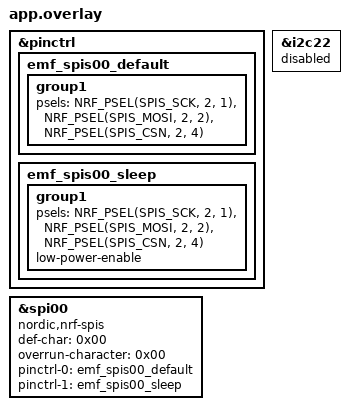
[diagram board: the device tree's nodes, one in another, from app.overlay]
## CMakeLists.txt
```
cmake_minimum_required(VERSION 3.20.0)

set(DTC_OVERLAY_FILE "${CMAKE_CURRENT_SOURCE_DIR}/app.overlay" CACHE STRING "" FORCE)

find_package(Zephyr REQUIRED HINTS $ENV{ZEPHYR_BASE})

project(ble_gatt_service_try)

target_sources(app PRIVATE src/main.c src/emf_data.c src/emf_spi.c)

target_compile_definitions(app PRIVATE
  EMF_SPIS_BOARD_NAME="XIAO"
)
```

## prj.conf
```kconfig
CONFIG_MULTITHREADING=y

CONFIG_BT=y
CONFIG_BT_PERIPHERAL=y
CONFIG_BT_DEVICE_NAME="XIAO_EMF"
CONFIG_BT_MAX_CONN=1

CONFIG_BT_LONG_WQ_PRIO=0
CONFIG_SYSTEM_WORKQUEUE_STACK_SIZE=8192
CONFIG_BT_LONG_WQ_STACK_SIZE=8192
CONFIG_BT_RX_STACK_SIZE=4096
CONFIG_BT_HCI_TX_STACK_SIZE=2048
CONFIG_MPSL_WORK_STACK_SIZE=8192
CONFIG_STACK_SENTINEL=y
CONFIG_THREAD_STACK_INFO=y
CONFIG_INIT_STACKS=y

CONFIG_LOG=y
CONFIG_PRINTK=y
CONFIG_MAIN_STACK_SIZE=8192

CONFIG_SERIAL=y
CONFIG_UART_INTERRUPT_DRIVEN=y

CONFIG_SPI=y
CONFIG_SPI_SLAVE=y
CONFIG_NRFX_SPIS=y

CONFIG_BT_BUF_ACL_TX_SIZE=251
CONFIG_BT_BUF_ACL_RX_SIZE=251
CONFIG_BT_L2CAP_TX_MTU=247
CONFIG_BT_CTLR_DATA_LENGTH_MAX=251
```

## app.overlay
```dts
#include <zephyr/dt-bindings/pinctrl/nrf-pinctrl.h>

&pinctrl {
	emf_spis00_default: emf_spis00_default {
		group1 {
			psels = <NRF_PSEL(SPIS_SCK, 2, 1)>,
				<NRF_PSEL(SPIS_MOSI, 2, 2)>,
				<NRF_PSEL(SPIS_CSN, 2, 4)>;
		};
	};

	emf_spis00_sleep: emf_spis00_sleep {
		group1 {
			psels = <NRF_PSEL(SPIS_SCK, 2, 1)>,
				<NRF_PSEL(SPIS_MOSI, 2, 2)>,
				<NRF_PSEL(SPIS_CSN, 2, 4)>;
			low-power-enable;
		};
	};
};

&spi00 {
	compatible = "nordic,nrf-spis";
	status = "okay";
	def-char = <0x00>;
	overrun-character = <0x00>;
	pinctrl-0 = <&emf_spis00_default>;
	pinctrl-1 = <&emf_spis00_sleep>;
	pinctrl-names = "default", "sleep";
	/delete-property/ rx-delay-supported;
	/delete-property/ rx-delay;
};

&i2c22 {
	status = "disabled";
};
```

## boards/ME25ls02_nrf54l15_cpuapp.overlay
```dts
#include <zephyr/dt-bindings/pinctrl/nrf-pinctrl.h>

&pinctrl {
	emf_spis00_default: emf_spis00_default {
		group1 {
			psels = <NRF_PSEL(SPIS_SCK, 2, 6)>,
				<NRF_PSEL(SPIS_MOSI, 2, 8)>,
				<NRF_PSEL(SPIS_MISO, 2, 9)>,
				<NRF_PSEL(SPIS_CSN, 2, 10)>;
		};
	};

	emf_spis00_sleep: emf_spis00_sleep {
		group1 {
			psels = <NRF_PSEL(SPIS_SCK, 2, 6)>,
				<NRF_PSEL(SPIS_MOSI, 2, 8)>,
				<NRF_PSEL(SPIS_MISO, 2, 9)>,
				<NRF_PSEL(SPIS_CSN, 2, 10)>;
			low-power-enable;
		};
	};
};

&spi00 {
	compatible = "nordic,nrf-spis";
	status = "okay";
	def-char = <0x00>;
	overrun-character = <0x00>;
	pinctrl-0 = <&emf_spis00_default>;
	pinctrl-1 = <&emf_spis00_sleep>;
	pinctrl-names = "default", "sleep";
	/delete-property/ rx-delay-supported;
	/delete-property/ rx-delay;
};
```

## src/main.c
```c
#include <zephyr/kernel.h>
#include <zephyr/types.h>
#include <zephyr/sys/printk.h>

#include <string.h>
#include <errno.h>

#include <zephyr/bluetooth/bluetooth.h>
#include <zephyr/bluetooth/conn.h>
#include <zephyr/bluetooth/gatt.h>
#include <zephyr/bluetooth/uuid.h>

#include "emf_data.h"

/*
 * BLE services:
 *
 * 1) Battery Service
 *    Service UUID:        0x180F
 *    Battery Level UUID:  0x2A19, read + notify
 *    BATS UUID:           0x2BED, read + notify
 *
 * 2) Data Service
 *    Service UUID:        00000000-8e22-4541-9d4c-21edae82ed19
 *    emf_values UUID:     00000001-8e22-4541-9d4c-21edae82ed19
 *    Properties:          indicate
 *    Payload size:        200 bytes
 */

#define EMF_VALUES_SIZE 200
#define EMF_PAYLOAD_DELAY_MS 2000

#define DATA_SERVICE_UUID_VAL \
	BT_UUID_128_ENCODE(0x00000000, 0x8e22, 0x4541, 0x9d4c, 0x21edae82ed19)

#define EMF_VALUES_UUID_VAL \
	BT_UUID_128_ENCODE(0x00000001, 0x8e22, 0x4541, 0x9d4c, 0x21edae82ed19)

static struct bt_uuid_128 data_service_uuid =
	BT_UUID_INIT_128(DATA_SERVICE_UUID_VAL);

static struct bt_uuid_128 emf_values_uuid =
	BT_UUID_INIT_128(EMF_VALUES_UUID_VAL);

/* Current BLE connection */
static struct bt_conn *current_conn;

/* Battery values */
static uint8_t battery_level = 95;
static uint8_t battery_status = 0;

/* CCC states */
static bool battery_level_notify_enabled;
static bool battery_status_notify_enabled;
static bool emf_indicate_enabled;

/* EMF data */
static uint8_t emf_values[EMF_VALUES_SIZE];
static uint8_t emf_payload[EMF_PAYLOAD_SIZE];
static size_t emf_payload_offset;
static bool emf_indication_busy;
static int64_t next_emf_message_time;

/* ------------------------------------------------ */
/* Read callbacks                                   */
/* ------------------------------------------------ */

static ssize_t read_u8_value(struct bt_conn *conn,
			     const struct bt_gatt_attr *attr,
			     void *buf,
			     uint16_t len,
			     uint16_t offset)
{
	const uint8_t *value = attr->user_data;

	return bt_gatt_attr_read(conn, attr, buf, len, offset,
				 value, sizeof(*value));
}

static ssize_t read_emf_values(struct bt_conn *conn,
			       const struct bt_gatt_attr *attr,
			       void *buf,
			       uint16_t len,
			       uint16_t offset)
{
	const uint8_t *value = attr->user_data;

	return bt_gatt_attr_read(conn, attr, buf, len, offset,
				 value, EMF_VALUES_SIZE);
}

/* ------------------------------------------------ */
/* CCC callbacks                                    */
/* ------------------------------------------------ */

static void battery_level_ccc_changed(const struct bt_gatt_attr *attr,
				      uint16_t value)
{
	battery_level_notify_enabled = (value == BT_GATT_CCC_NOTIFY);

	printk("Battery Level notify: %s\n",
	       battery_level_notify_enabled ? "enabled" : "disabled");
}

static void battery_status_ccc_changed(const struct bt_gatt_attr *attr,
				       uint16_t value)
{
	battery_status_notify_enabled = (value == BT_GATT_CCC_NOTIFY);

	printk("Battery Status notify: %s\n",
	       battery_status_notify_enabled ? "enabled" : "disabled");
}

static void emf_ccc_changed(const struct bt_gatt_attr *attr,
			    uint16_t value)
{
	emf_indicate_enabled = (value == BT_GATT_CCC_INDICATE);

	if (emf_indicate_enabled) {
		emf_payload_offset = 0;
		next_emf_message_time = 0;
	}

	printk("EMF indication: %s\n",
	       emf_indicate_enabled ? "enabled" : "disabled");
}

/* ------------------------------------------------ */
/* Battery Service                                  */
/* ------------------------------------------------ */

/*
 * battery_svc attrs:
 *
 * [0] Primary Service
 *
 * Battery Level:
 * [1] Characteristic Declaration
 * [2] Characteristic Value
 * [3] Characteristic User Description
 * [4] CCC
 *
 * Battery Status:
 * [5] Characteristic Declaration
 * [6] Characteristic Value
 * [7] Characteristic User Description
 * [8] CCC
 */

BT_GATT_SERVICE_DEFINE(battery_svc,
	BT_GATT_PRIMARY_SERVICE(BT_UUID_DECLARE_16(0x180F)),

	BT_GATT_CHARACTERISTIC(BT_UUID_DECLARE_16(0x2A19),
			       BT_GATT_CHRC_READ | BT_GATT_CHRC_NOTIFY,
			       BT_GATT_PERM_READ,
			       read_u8_value,
			       NULL,
			       &battery_level),

	BT_GATT_CUD("Battery Level", BT_GATT_PERM_READ),

	BT_GATT_CCC(battery_level_ccc_changed,
		    BT_GATT_PERM_READ | BT_GATT_PERM_WRITE),

	BT_GATT_CHARACTERISTIC(BT_UUID_DECLARE_16(0x2BED),
			       BT_GATT_CHRC_READ | BT_GATT_CHRC_NOTIFY,
			       BT_GATT_PERM_READ,
			       read_u8_value,
			       NULL,
			       &battery_status),

	BT_GATT_CUD("Battery Status", BT_GATT_PERM_READ),

	BT_GATT_CCC(battery_status_ccc_changed,
		    BT_GATT_PERM_READ | BT_GATT_PERM_WRITE)
);

/* ------------------------------------------------ */
/* Data Service                                     */
/* ------------------------------------------------ */

/*
 * data_svc attrs:
 *
 * [0] Primary Service
 * [1] Characteristic Declaration
 * [2] Characteristic Value
 * [3] Characteristic User Description
 * [4] CCC
 */

BT_GATT_SERVICE_DEFINE(data_svc,
	BT_GATT_PRIMARY_SERVICE(&data_service_uuid.uuid),

	BT_GATT_CHARACTERISTIC(&emf_values_uuid.uuid,
			       BT_GATT_CHRC_READ | BT_GATT_CHRC_INDICATE,
			       BT_GATT_PERM_READ,
			       read_emf_values,
			       NULL,
			       emf_values),

	BT_GATT_CUD("EMF Values", BT_GATT_PERM_READ),

	BT_GATT_CCC(emf_ccc_changed,
		    BT_GATT_PERM_READ | BT_GATT_PERM_WRITE)
);

/* ------------------------------------------------ */
/* Battery notify                                   */
/* ------------------------------------------------ */

static void send_battery_level_notify(void)
{
	if (!current_conn || !battery_level_notify_enabled) {
		return;
	}

	int err = bt_gatt_notify(current_conn,
				 &battery_svc.attrs[2],
				 &battery_level,
				 sizeof(battery_level));

	if (err) {
		printk("Battery Level notify failed: %d\n", err);
	}
}

static void send_battery_status_notify(void)
{
	if (!current_conn || !battery_status_notify_enabled) {
		return;
	}

	int err = bt_gatt_notify(current_conn,
				 &battery_svc.attrs[6],
				 &battery_status,
				 sizeof(battery_status));

	if (err) {
		printk("Battery Status notify failed: %d\n", err);
	}
}

/* ------------------------------------------------ */
/* EMF indication                                   */
/* ------------------------------------------------ */

static void emf_indication_complete(struct bt_conn *conn,
				    struct bt_gatt_indicate_params *params,
				    uint8_t err)
{
	emf_indication_busy = false;

	if (emf_payload_offset >= EMF_PAYLOAD_SIZE) {
		next_emf_message_time = k_uptime_get() + EMF_PAYLOAD_DELAY_MS;
	}

	printk("EMF indication complete, err=%u\n", err);
}

static struct bt_gatt_indicate_params emf_ind_params;

static int send_emf_values_indication(const uint8_t *data, uint16_t size)
{
	if (!current_conn) {
		return -ENOTCONN;
	}

	if (!emf_indicate_enabled) {
		return -EACCES;
	}

	if (emf_indication_busy) {
		return -EBUSY;
	}

	if (size > EMF_VALUES_SIZE) {
		return -EINVAL;
	}

	memcpy(emf_values, data, size);

	emf_ind_params.attr = &data_svc.attrs[2];
	emf_ind_params.func = emf_indication_complete;
	emf_ind_params.data = emf_values;
	emf_ind_params.len = size;

	emf_indication_busy = true;

	int err = bt_gatt_indicate(current_conn, &emf_ind_params);

	if (err) {
		emf_indication_busy = false;
		printk("EMF indication failed: %d\n", err);
	}

	return err;
}

static int send_next_emf_chunk(void)
{
	size_t chunk_size;
	int err;

	if (emf_payload_offset >= EMF_PAYLOAD_SIZE) {
		emf_payload_offset = 0;
	}

	chunk_size = EMF_PAYLOAD_SIZE - emf_payload_offset;
	if (chunk_size > EMF_VALUES_SIZE) {
		chunk_size = EMF_VALUES_SIZE;
	}

	err = send_emf_values_indication(&emf_payload[emf_payload_offset],
					 chunk_size);
	if (err) {
		return err;
	}

	printk("EMF chunk sent: offset=%u size=%u\n",
	       (unsigned int)emf_payload_offset,
	       (unsigned int)chunk_size);

	emf_payload_offset += chunk_size;

	return 0;
}

/* ------------------------------------------------ */
/* Connection callbacks                             */
/* ------------------------------------------------ */

static int start_advertising(void);
static void advertising_work_handler(struct k_work *work);

static K_WORK_DELAYABLE_DEFINE(advertising_work, advertising_work_handler);

static void connected(struct bt_conn *conn, uint8_t err)
{
	if (err) {
		printk("Connection failed, err=%u\n", err);
		return;
	}

	current_conn = bt_conn_ref(conn);

	printk("Connected\n");
}

static void disconnected(struct bt_conn *conn, uint8_t reason)
{
	printk("Disconnected, reason=%u\n", reason);

	if (current_conn) {
		bt_conn_unref(current_conn);
		current_conn = NULL;
	}

	battery_level_notify_enabled = false;
	battery_status_notify_enabled = false;
	emf_indicate_enabled = false;
	emf_indication_busy = false;

	k_work_schedule(&advertising_work, K_MSEC(100));
}

BT_CONN_CB_DEFINE(conn_callbacks) = {
	.connected = connected,
	.disconnected = disconnected,
};

/* ------------------------------------------------ */
/* Advertising                                      */
/* ------------------------------------------------ */

static const struct bt_data ad[] = {
	BT_DATA_BYTES(BT_DATA_FLAGS, BT_LE_AD_GENERAL | BT_LE_AD_NO_BREDR),

	BT_DATA(BT_DATA_NAME_COMPLETE,
		CONFIG_BT_DEVICE_NAME,
		sizeof(CONFIG_BT_DEVICE_NAME) - 1),

	BT_DATA_BYTES(BT_DATA_UUID16_ALL,
		      BT_UUID_16_ENCODE(0x180F)),
};

static int start_advertising(void)
{
	int err = bt_le_adv_start(BT_LE_ADV_CONN_FAST_1,
				  ad,
				  ARRAY_SIZE(ad),
				  NULL,
				  0);

	if (err) {
		return err;
	}

	printk("Advertising started as %s\n", CONFIG_BT_DEVICE_NAME);

	return 0;
}

static void advertising_work_handler(struct k_work *work)
{
	int err = start_advertising();

	if (err) {
		printk("Advertising restart failed: %d\n", err);
	}
}

/* ------------------------------------------------ */
/* Main                                             */
/* ------------------------------------------------ */

int main(void)
{
	int err;
	int64_t last_battery_update = -10000;

	printk("Starting BLE GATT server\n");

	emf_data_generate(emf_payload, sizeof(emf_payload));
	printk("EMF payload generated, size=%u\n",
	       (unsigned int)sizeof(emf_payload));

	err = bt_enable(NULL);
	if (err) {
		printk("Bluetooth init failed: %d\n", err);
		return 0;
	}

	printk("Bluetooth initialized\n");

	err = start_advertising();
	if (err) {
		printk("Advertising start failed: %d\n", err);
		return 0;
	}

	while (1) {
		int64_t now = k_uptime_get();

		if ((now - last_battery_update) >= 10000) {
			if (battery_level > 0) {
				battery_level--;
			} else {
				battery_level = 100;
			}

			battery_status ^= 0x01;

			send_battery_level_notify();
			send_battery_status_notify();

			last_battery_update = now;
		}

		if (current_conn && emf_indicate_enabled && !emf_indication_busy &&
		    now >= next_emf_message_time) {
			err = send_next_emf_chunk();

			if (err == -EMSGSIZE) {
				printk("EMF chunk too large for current MTU\n");
			} else if (err) {
				printk("EMF chunk error: %d\n", err);
			}
		}

		k_sleep(K_MSEC(10));
	}

	return 0;
}	
```

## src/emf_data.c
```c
#include "emf_data.h"

#include <math.h>

#include <zephyr/random/random.h>

#ifndef M_PI
#define M_PI 3.14159265358979323846
#endif

static float speed[EMF_SAMPLE_COUNT];

float indenter_speed(float *v, size_t len)
{
	const float g = 9.80665f;
	const float fs_mhz = 40.0f;
	const float fs = fs_mhz * 1000000.0f;
	const float ts = 1.0f / fs;
	const float g_ts = g * ts;
	const float t_full = 50.0f;
	const float t_emf = (float)len / fs_mhz;
	const float t_mg = (t_emf - t_full) / 2.0f;
	const float v_t0 = 2.05f;
	const float v_t2 = -1.0f;

	size_t t0_i = (size_t)(t_mg * fs_mhz + 1.0f);
	size_t t2_i = (size_t)((t_mg + t_full) * fs_mhz + 1.0f);

	if (t0_i > len) {
		t0_i = len;
	}

	if (t2_i > len) {
		t2_i = len;
	}

	float v_buff = v_t0 - g_ts;

	for (size_t i = t0_i; i-- > 0;) {
		v[i] = v_buff;
		v_buff -= g_ts;
	}

	float t_buff = 0.0f;
	float t_pi = (float)M_PI / (float)(t2_i - t0_i);
	float amp = (v_t0 - v_t2) / 2.0f;
	float offset = amp + v_t2;

	for (size_t i = t0_i; i < t2_i; ++i) {
		v[i] = amp * cosf(t_buff) + offset;
		t_buff += t_pi;
	}

	v_buff = v_t2 + g_ts;

	for (size_t i = t2_i; i < len; ++i) {
		v[i] = v_buff;
		v_buff += g_ts;
	}

	return v_t0;
}

void emf_data_generate(uint8_t *dst, size_t len)
{
	if (len < EMF_PAYLOAD_SIZE) {
		return;
	}

	indenter_speed(speed, EMF_SAMPLE_COUNT);

	for (size_t i = 0; i < EMF_SAMPLE_COUNT; ++i) {
		float value = (speed[i] * 850.0f) + 100.0f;

		// if (value < 0.0f) {
		// 	value += 4095.0f;
		// }

		int16_t number = (int16_t)value;
		uint16_t encoded = (uint16_t)number;

		dst[i * 2] = encoded & 0xff;
		dst[i * 2 + 1] = encoded >> 8;
	}
}
```

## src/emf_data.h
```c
#ifndef EMF_DATA_H_
#define EMF_DATA_H_

#include <stddef.h>
#include <stdint.h>

#define EMF_SAMPLE_COUNT 8000
#define EMF_PAYLOAD_SIZE (EMF_SAMPLE_COUNT * sizeof(uint16_t))

float indenter_speed(float *v, size_t len);
void emf_data_generate(uint8_t *dst, size_t len);

#endif /* EMF_DATA_H_ */
```

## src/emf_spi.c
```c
#include "emf_spi.h"

#include <errno.h>
#include <string.h>

#include <hal/nrf_gpio.h>
#include <zephyr/device.h>
#include <zephyr/drivers/spi.h>
#include <zephyr/kernel.h>
#include <zephyr/sys/printk.h>
#include <zephyr/toolchain.h>

#include "emf_data.h"

#define EMF_SPI_NODE DT_NODELABEL(spi00)
#ifndef EMF_SPIS_SCK_PORT
#define EMF_SPIS_SCK_PORT 2
#endif
#ifndef EMF_SPIS_SCK_PIN_NUM
#define EMF_SPIS_SCK_PIN_NUM 1
#endif
#ifndef EMF_SPIS_MOSI_PORT
#define EMF_SPIS_MOSI_PORT 2
#endif
#ifndef EMF_SPIS_MOSI_PIN_NUM
#define EMF_SPIS_MOSI_PIN_NUM 2
#endif
#ifndef EMF_SPIS_CSN_PORT
#define EMF_SPIS_CSN_PORT 2
#endif
#ifndef EMF_SPIS_CSN_PIN_NUM
#define EMF_SPIS_CSN_PIN_NUM 4
#endif
#ifndef EMF_SPIS_BOARD_NAME
#define EMF_SPIS_BOARD_NAME "board"
#endif

#define EMF_SPIS_SCK_PIN NRF_GPIO_PIN_MAP(EMF_SPIS_SCK_PORT, EMF_SPIS_SCK_PIN_NUM)
#define EMF_SPIS_MOSI_PIN NRF_GPIO_PIN_MAP(EMF_SPIS_MOSI_PORT, EMF_SPIS_MOSI_PIN_NUM)
#define EMF_SPIS_CSN_PIN NRF_GPIO_PIN_MAP(EMF_SPIS_CSN_PORT, EMF_SPIS_CSN_PIN_NUM)
#define EMF_SPI_RX_THREAD_STACK_SIZE 4096
#define EMF_SPI_RX_THREAD_PRIORITY 5

static const struct device *const emf_spi = DEVICE_DT_GET(EMF_SPI_NODE);

static const struct spi_config emf_spi_config = {
	.frequency = 500000,
	.operation = SPI_OP_MODE_SLAVE | SPI_WORD_SET(8) |
		     SPI_TRANSFER_MSB | SPI_MODE_CPHA,
};

static uint8_t payload[EMF_PAYLOAD_SIZE] __aligned(4);
static volatile bool frame_ready;
static volatile bool frame_received_event;
static volatile bool rx_armed;
static volatile int last_rx_error;
static volatile uint32_t xfer_done_count;
static volatile uint32_t rx_error_count;
static bool spi_initialized;
static uint32_t frame_count;
static uint8_t last_logged_csn = 0xff;
static uint32_t last_logged_xfer_done_count;
static uint32_t last_logged_rx_error_count;

static K_THREAD_STACK_DEFINE(emf_spi_rx_stack, EMF_SPI_RX_THREAD_STACK_SIZE);
static struct k_thread emf_spi_rx_thread;

static uint32_t payload_checksum(void)
{
	uint32_t checksum = 0;

	for (size_t i = 0; i < EMF_PAYLOAD_SIZE; i++) {
		checksum += payload[i];
	}

	return checksum;
}

static void emf_spi_rx_thread_fn(void *p1, void *p2, void *p3)
{
	struct spi_buf rx_buf = {
		.buf = payload,
		.len = EMF_PAYLOAD_SIZE,
	};
	struct spi_buf_set rx_set = {
		.buffers = &rx_buf,
		.count = 1,
	};
	int err;

	ARG_UNUSED(p1);
	ARG_UNUSED(p2);
	ARG_UNUSED(p3);

	while (1) {
		if (frame_ready) {
			k_sleep(K_MSEC(1));
			continue;
		}

		memset(payload, 0, sizeof(payload));
		rx_armed = true;

		err = spi_read(emf_spi, &emf_spi_config, &rx_set);

		rx_armed = false;
		last_rx_error = err;

		if (err) {
			rx_error_count++;
			k_sleep(K_MSEC(10));
			continue;
		}

		xfer_done_count++;
		frame_ready = true;
		frame_received_event = true;
	}
}

int emf_spi_init(void)
{
	if (spi_initialized) {
		return 0;
	}

	if (!device_is_ready(emf_spi)) {
		printk("EMF SPIS device is not ready\n");
		return -ENODEV;
	}

	spi_initialized = true;

	k_thread_create(&emf_spi_rx_thread,
			emf_spi_rx_stack,
			K_THREAD_STACK_SIZEOF(emf_spi_rx_stack),
			emf_spi_rx_thread_fn,
			NULL,
			NULL,
			NULL,
			K_PRIO_PREEMPT(EMF_SPI_RX_THREAD_PRIORITY),
			0,
			K_NO_WAIT);

	printk("EMF SPIS ready: %s spi00 slave, CSN=P%u.%u, SCK=P%u.%u, MOSI=P%u.%u, mode=1, frame=%u bytes\n",
	       EMF_SPIS_BOARD_NAME,
	       EMF_SPIS_CSN_PORT,
	       EMF_SPIS_CSN_PIN_NUM,
	       EMF_SPIS_SCK_PORT,
	       EMF_SPIS_SCK_PIN_NUM,
	       EMF_SPIS_MOSI_PORT,
	       EMF_SPIS_MOSI_PIN_NUM,
	       (unsigned int)EMF_PAYLOAD_SIZE);

	return 0;
}

void emf_spi_poll_debug(void)
{
	uint8_t csn = nrf_gpio_pin_read(EMF_SPIS_CSN_PIN);
	uint8_t sck = nrf_gpio_pin_read(EMF_SPIS_SCK_PIN);
	uint8_t mosi = nrf_gpio_pin_read(EMF_SPIS_MOSI_PIN);

	if (csn != last_logged_csn ||
	    xfer_done_count != last_logged_xfer_done_count ||
	    rx_error_count != last_logged_rx_error_count) {
		printk("EMF SPIS status: armed=%u ready=%u csn=%u sck=%u mosi=%u done=%u errors=%u err=%d first=%02x %02x %02x %02x\n",
		       rx_armed ? 1 : 0,
		       frame_ready ? 1 : 0,
		       csn,
		       sck,
		       mosi,
		       xfer_done_count,
		       rx_error_count,
		       last_rx_error,
		       payload[0],
		       payload[1],
		       payload[2],
		       payload[3]);

		last_logged_csn = csn;
		last_logged_xfer_done_count = xfer_done_count;
		last_logged_rx_error_count = rx_error_count;
	}
}

bool emf_spi_frame_ready(void)
{
	return frame_ready;
}

bool emf_spi_take_frame_received_event(void)
{
	bool event = frame_received_event;

	frame_received_event = false;

	return event;
}

const uint8_t *emf_spi_payload(void)
{
	return payload;
}

void emf_spi_release_frame(void)
{
	frame_ready = false;

	frame_count++;
	printk("EMF SPIS frame #%u rx: first=%02x %02x %02x %02x %02x %02x %02x %02x checksum=%u\n",
	       frame_count,
	       payload[0],
	       payload[1],
	       payload[2],
	       payload[3],
	       payload[4],
	       payload[5],
	       payload[6],
	       payload[7],
	       payload_checksum());
}
```

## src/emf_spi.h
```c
#ifndef EMF_SPI_H_
#define EMF_SPI_H_

#include <stdbool.h>
#include <stddef.h>
#include <stdint.h>

int emf_spi_init(void);
void emf_spi_poll_debug(void);
bool emf_spi_frame_ready(void);
bool emf_spi_take_frame_received_event(void);
const uint8_t *emf_spi_payload(void);
void emf_spi_release_frame(void);

#endif /* EMF_SPI_H_ */
```

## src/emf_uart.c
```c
#include "emf_uart.h"

#include <errno.h>

#include <zephyr/device.h>
#include <zephyr/drivers/uart.h>
#include <zephyr/kernel.h>
#include <zephyr/sys/printk.h>

#include "emf_data.h"

#define EMF_UART_NODE DT_NODELABEL(uart20)

static const struct device *const emf_uart = DEVICE_DT_GET(EMF_UART_NODE);

static uint8_t payload[EMF_PAYLOAD_SIZE];
static volatile size_t rx_len;
static volatile uint32_t error_count;
static volatile int last_error;
static volatile bool frame_ready;
static volatile bool frame_received_event;

static void reset_rx(void)
{
	rx_len = 0;
	uart_irq_rx_enable(emf_uart);
}

static void process_rx_byte(uint8_t byte)
{
	if (rx_len < EMF_PAYLOAD_SIZE) {
		payload[rx_len++] = byte;
	}

	if (rx_len >= EMF_PAYLOAD_SIZE) {
		uart_irq_rx_disable(emf_uart);
		frame_ready = true;
		frame_received_event = true;
	}
}

static void process_rx_data(const uint8_t *data, size_t len)
{
	for (size_t i = 0; i < len; i++) {
		process_rx_byte(data[i]);
		if (frame_ready) {
			break;
		}
	}
}

static void emf_uart_isr(const struct device *dev, void *user_data)
{
	ARG_UNUSED(user_data);
	uint8_t rx_byte;

	if (!uart_irq_update(dev) || !uart_irq_rx_ready(dev)) {
		return;
	}

	while (!frame_ready && uart_fifo_read(dev, &rx_byte, 1) == 1) {
		process_rx_data(&rx_byte, 1);
	}
}

int emf_uart_init(void)
{
	if (!device_is_ready(emf_uart)) {
		printk("EMF UART is not ready\n");
		return -ENODEV;
	}

	uart_irq_callback_user_data_set(emf_uart, emf_uart_isr, NULL);
	reset_rx();

	printk("EMF UART RX ready: uart20, 115200 8N1, frame=%u bytes\n",
	       (unsigned int)EMF_PAYLOAD_SIZE);

	return 0;
}

size_t emf_uart_rx_len(void)
{
	return rx_len;
}

uint32_t emf_uart_error_count(void)
{
	return error_count;
}

int emf_uart_last_error(void)
{
	return last_error;
}

bool emf_uart_frame_ready(void)
{
	return frame_ready;
}

bool emf_uart_take_frame_received_event(void)
{
	bool event = frame_received_event;

	frame_received_event = false;

	return event;
}

const uint8_t *emf_uart_payload(void)
{
	return payload;
}

void emf_uart_release_frame(void)
{
	frame_ready = false;
	reset_rx();
}
```

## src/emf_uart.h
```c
#ifndef EMF_UART_H_
#define EMF_UART_H_

#include <stdbool.h>
#include <stddef.h>
#include <stdint.h>

int emf_uart_init(void);
size_t emf_uart_rx_len(void);
uint32_t emf_uart_error_count(void);
int emf_uart_last_error(void);
bool emf_uart_frame_ready(void);
bool emf_uart_take_frame_received_event(void);
const uint8_t *emf_uart_payload(void);
void emf_uart_release_frame(void);

#endif /* EMF_UART_H_ */
```
